VERSION ""

NS_ :

BS_:

BU_: XXX

BO_ 339 NEW_MSG_1: 8 XXX
 SG_ VEHICLE_SPEED : 23|8@0+ (1,0) [0|255] "" XXX
 SG_ ESC_SWITCH_1ST : 2|1@1+ (1,0) [0|3] "" XXX
 SG_ ESC_SWITCH_2nd : 12|0@0+ (1,0) [0|3] "" XXX

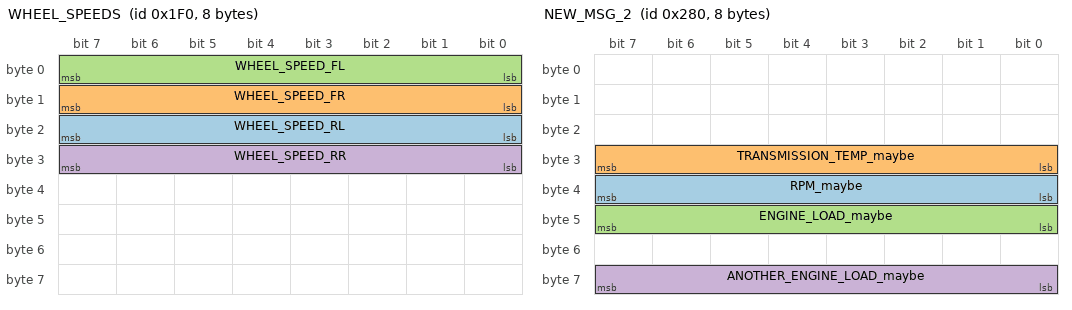
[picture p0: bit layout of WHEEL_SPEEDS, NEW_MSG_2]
BO_ 496 WHEEL_SPEEDS: 8 XXX
 SG_ WHEEL_SPEED_RL : 23|8@0+ (1,0) [0|255] "" XXX
 SG_ WHEEL_SPEED_FR : 15|8@0+ (1,0) [0|255] "" XXX
 SG_ WHEEL_SPEED_FL : 7|8@0+ (1,0) [0|255] "" XXX
 SG_ WHEEL_SPEED_RR : 31|8@0+ (1,0) [0|255] "" XXX

BO_ 640 NEW_MSG_2: 8 XXX
 SG_ RPM_maybe : 39|8@0+ (1,0) [0|255] "" XXX
 SG_ TRANSMISSION_TEMP_maybe : 31|8@0+ (1,0) [0|255] "" XXX
 SG_ ENGINE_LOAD_maybe : 47|8@0+ (1,0) [0|255] "" XXX
 SG_ ANOTHER_ENGINE_LOAD_maybe : 63|8@0+ (1,0) [0|255] "" XXX

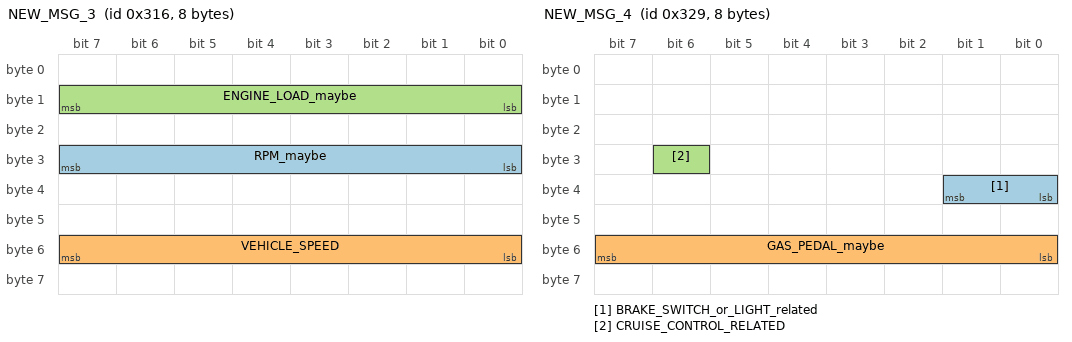
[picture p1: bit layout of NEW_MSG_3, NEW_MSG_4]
BO_ 790 NEW_MSG_3: 8 XXX
 SG_ RPM_maybe : 31|8@0+ (1,0) [0|255] "" XXX
 SG_ VEHICLE_SPEED : 55|8@0+ (1,0) [0|255] "" XXX
 SG_ ENGINE_LOAD_maybe : 15|8@0+ (1,0) [0|255] "" XXX

BO_ 809 NEW_MSG_4: 8 XXX
 SG_ BRAKE_SWITCH_or_LIGHT_related : 33|2@0+ (1,0) [0|255] "" XXX
 SG_ GAS_PEDAL_maybe : 55|8@0+ (1,0) [0|255] "" XXX
 SG_ CRUISE_CONTROL_RELATED : 30|1@0+ (1,0) [0|3] "" XXX

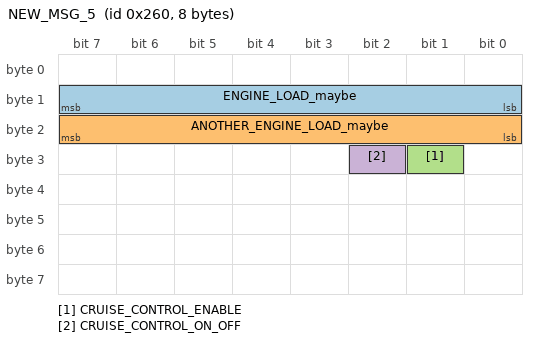
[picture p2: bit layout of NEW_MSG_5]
BO_ 608 NEW_MSG_5: 8 XXX
 SG_ ENGINE_LOAD_maybe : 15|8@0+ (1,0) [0|255] "" XXX
 SG_ ANOTHER_ENGINE_LOAD_maybe : 23|8@0+ (1,0) [0|255] "" XXX
 SG_ CRUISE_CONTROL_ENABLE : 25|1@0+ (1,0) [0|1] "" XXX
 SG_ CRUISE_CONTROL_ON_OFF : 26|1@0+ (1,0) [0|1] "" XXX

BO_ 672 NEW_MSG_6: 8 XXX
